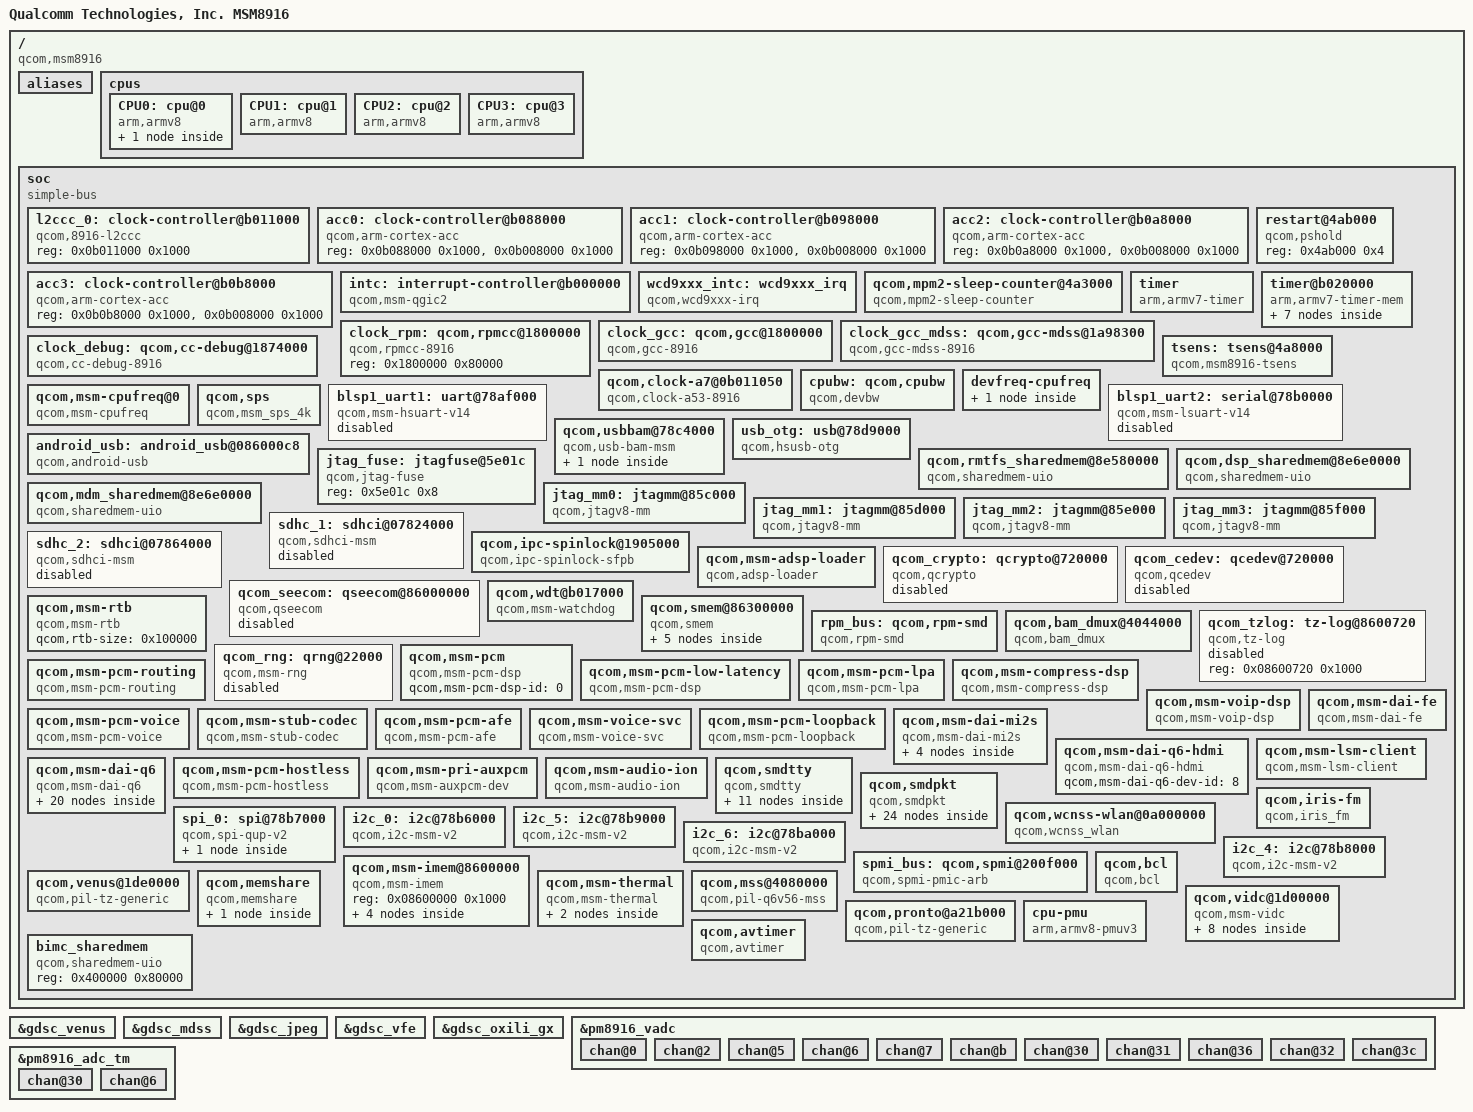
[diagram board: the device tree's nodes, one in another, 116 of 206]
/* Copyright (c) 2013-2014, The Linux Foundation. All rights reserved.
 *
 * This program is free software; you can redistribute it and/or modify
 * it under the terms of the GNU General Public License version 2 and
 * only version 2 as published by the Free Software Foundation.
 *
 * This program is distributed in the hope that it will be useful,
 * but WITHOUT ANY WARRANTY; without even the implied warranty of
 * MERCHANTABILITY or FITNESS FOR A PARTICULAR PURPOSE.  See the
 * GNU General Public License for more details.
 */

#include "skeleton64.dtsi"
#include <dt-bindings/clock/msm-clocks-8916.h>

/ {
	model = "Qualcomm Technologies, Inc. MSM8916";
	compatible = "qcom,msm8916";
	qcom,msm-id =	<206 0>,
			<248 0>,
			<249 0>,
			<250 0>;

	interrupt-parent = <&intc>;
	aliases {
		sdhc1 = &sdhc_1; /* SDC1 eMMC slot */
		sdhc2 = &sdhc_2; /* SDC2 SD card slot */

		/* smdtty devices */
		smd1 = &smdtty_apps_fm;
		smd2 = &smdtty_apps_riva_bt_acl;
		smd3 = &smdtty_apps_riva_bt_cmd;
		smd4 = &smdtty_mbalbridge;
		smd5 = &smdtty_apps_riva_ant_cmd;
		smd6 = &smdtty_apps_riva_ant_data;
		smd7 = &smdtty_data1;
		smd8 = &smdtty_data4;
		smd11 = &smdtty_data11;
		smd21 = &smdtty_data21;
		smd36 = &smdtty_loopback;

		spi0 = &spi_0; /* SPI0 controller device */
		i2c0 = &i2c_0; /* I2C0 controller device */
		i2c5 = &i2c_5; /* I2C5 controller device */
		i2c6 = &i2c_6; /* I2C6 NFC qup6 device */
		i2c4 = &i2c_4; /* I2C4 controller device */
	};

	cpus {
		#address-cells = <1>;
		#size-cells = <0>;

		CPU0: cpu@0 {
			device_type = "cpu";
			compatible = "arm,armv8";
			reg = <0x0>;
			enable-method = "qcom,arm-cortex-acc";
			qcom,acc = <&acc0>;
			next-level-cache = <&L2_0>;
			L2_0: l2-cache {
			      compatible = "arm,arch-cache";
			      cache-level = <2>;
			      power-domain = <&l2ccc_0>;
			};
		};

		CPU1: cpu@1 {
			device_type = "cpu";
			compatible = "arm,armv8";
			reg = <0x1>;
			enable-method = "qcom,arm-cortex-acc";
			qcom,acc = <&acc1>;
			next-level-cache = <&L2_0>;
		};

		CPU2: cpu@2 {
			device_type = "cpu";
			compatible = "arm,armv8";
			reg = <0x2>;
			enable-method = "qcom,arm-cortex-acc";
			qcom,acc = <&acc2>;
			next-level-cache = <&L2_0>;
		};

		CPU3: cpu@3 {
			device_type = "cpu";
			compatible = "arm,armv8";
			reg = <0x3>;
			enable-method = "qcom,arm-cortex-acc";
			qcom,acc = <&acc3>;
			next-level-cache = <&L2_0>;
		};
	};

	soc: soc { };
};

#include "msm8916-coresight.dtsi"
#include "msm8916-smp2p.dtsi"
#include "msm8916-pinctrl.dtsi"
#include "msm8916-camera.dtsi"
#include "msm8916-ipcrouter.dtsi"
#include "msm-gdsc-8916.dtsi"
#include "msm8916-iommu.dtsi"
#include "msm8916-gpu.dtsi"
#include "msm8916-mdss.dtsi"
#include "msm8916-mdss-pll.dtsi"
#include "msm8916-iommu-domains.dtsi"
#include "msm8916-bus.dtsi"
#include "msm8916-camera.dtsi"

&soc {
	#address-cells = <1>;
	#size-cells = <1>;
	ranges = <0 0 0 0xffffffff>;
	compatible = "simple-bus";

	l2ccc_0: clock-controller@b011000 {
		compatible = "qcom,8916-l2ccc";
		reg = <0x0b011000 0x1000>;
	};

	acc0:clock-controller@b088000 {
		compatible = "qcom,arm-cortex-acc";
		reg = <0x0b088000 0x1000>,
		      <0x0b008000 0x1000>;
	};

	acc1:clock-controller@b098000 {
		compatible = "qcom,arm-cortex-acc";
		reg = <0x0b098000 0x1000>,
		      <0x0b008000 0x1000>;
	};

	acc2:clock-controller@b0a8000 {
		compatible = "qcom,arm-cortex-acc";
		reg = <0x0b0a8000 0x1000>,
		      <0x0b008000 0x1000>;
	};

	acc3:clock-controller@b0b8000 {
		compatible = "qcom,arm-cortex-acc";
		reg = <0x0b0b8000 0x1000>,
		      <0x0b008000 0x1000>;
	};

	intc: interrupt-controller@b000000 {
		compatible = "qcom,msm-qgic2";
		interrupt-controller;
		#interrupt-cells = <3>;
		reg = <0x0b000000 0x1000>,
		<0x0b002000 0x1000>;
	};

	wcd9xxx_intc: wcd9xxx_irq {
		compatible = "qcom,wcd9xxx-irq";
		interrupt-controller;
		#interrupt-cells = <1>;
		interrupt-parent = <&intc>;
		interrupts = <0 68 0>;
		interrupt-names = "cdc-int";
	};

	restart@4ab000 {
		compatible = "qcom,pshold";
		reg = <0x4ab000 0x4>;
	};

	qcom,mpm2-sleep-counter@4a3000 {
		compatible = "qcom,mpm2-sleep-counter";
		reg = <0x4a3000 0x1000>;
		clock-frequency = <32768>;
	};

	timer {
		compatible = "arm,armv7-timer";
		interrupts = <1 2 0xf08>,
			     <1 3 0xf08>,
			     <1 4 0xf08>,
			     <1 1 0xf08>;
		clock-frequency = <19200000>;
	};

	timer@b020000 {
		#address-cells = <1>;
		#size-cells = <1>;
		ranges;
		compatible = "arm,armv7-timer-mem";
		reg = <0xb020000 0x1000>;
		clock-frequency = <19200000>;

		frame@b021000 {
			frame-number = <0>;
			interrupts = <0 8 0x4>,
				     <0 7 0x4>;
			reg = <0xb021000 0x1000>,
			      <0xb022000 0x1000>;
		};

		frame@b023000 {
			frame-number = <1>;
			interrupts = <0 9 0x4>;
			reg = <0xb023000 0x1000>;
			status = "disabled";
		};

		frame@b024000 {
			frame-number = <2>;
			interrupts = <0 10 0x4>;
			reg = <0xb024000 0x1000>;
			status = "disabled";
		};

		frame@b025000 {
			frame-number = <3>;
			interrupts = <0 11 0x4>;
			reg = <0xb025000 0x1000>;
			status = "disabled";
		};

		frame@b026000 {
			frame-number = <4>;
			interrupts = <0 12 0x4>;
			reg = <0xb026000 0x1000>;
			status = "disabled";
		};

		frame@b027000 {
			frame-number = <5>;
			interrupts = <0 13 0x4>;
			reg = <0xb027000 0x1000>;
			status = "disabled";
		};

		frame@b028000 {
			frame-number = <6>;
			interrupts = <0 14 0x4>;
			reg = <0xb028000 0x1000>;
			status = "disabled";
		};
	};

	clock_rpm: qcom,rpmcc@1800000 {
		compatible = "qcom,rpmcc-8916";
		reg = <0x1800000 0x80000>;
		reg-names = "cc_base";
		#clock-cells = <1>;

	};

	clock_gcc: qcom,gcc@1800000 {
		compatible = "qcom,gcc-8916";
		reg = <0x1800000 0x80000>,
		      <0xb016000 0x00040>;
		reg-names = "cc_base", "apcs_base";
		vdd_dig-supply = <&pm8916_s1_corner>;
		vdd_sr2_dig-supply = <&pm8916_s1_corner_ao>;
		vdd_sr2_pll-supply = <&pm8916_l7_ao>;
		clocks = <&clock_rpm clk_xo_clk_src>,
                         <&clock_rpm clk_xo_a_clk_src>;
		clock-names = "xo", "xo_a";
		#clock-cells = <1>;
	};

	clock_gcc_mdss: qcom,gcc-mdss@1a98300 {
		compatible = "qcom,gcc-mdss-8916";
		clocks = <&mdss_dsi0_pll clk_pixel_clk_src>,
			 <&mdss_dsi0_pll clk_byte_clk_src>;
		clock-names = "pixel_src", "byte_src";
		#clock-cells = <1>;
	};

	clock_debug: qcom,cc-debug@1874000 {
		compatible = "qcom,cc-debug-8916";
		reg = <0x1874000 0x4>,
		      <0xb01101c 0x8>;
		reg-names = "cc_base", "meas";
		clocks = <&clock_rpm clk_rpm_debug_mux>;
		clock-names = "rpm_debug_mux";
		#clock-cells = <1>;
	};

	tsens: tsens@4a8000 {
		compatible = "qcom,msm8916-tsens";
		reg = <0x4a8000 0x2000>,
		      <0x5c000  0x1000>;
		reg-names = "tsens_physical", "tsens_eeprom_physical";
		interrupts = <0 184 0>;
		qcom,sensors = <5>;
		qcom,slope = <3200 3200 3200 3200 3200>;
		qcom,sensor-id = <0 1 2 4 5>;
	};

	qcom,clock-a7@0b011050 {
		compatible = "qcom,clock-a53-8916";
		reg = <0x0b011050 0x8>;
		reg-names = "rcg-base";
		qcom,safe-freq = < 400000000 >;
		cpu-vdd-supply = <&apc_vreg_corner>;
		clocks = <&clock_gcc clk_gpll0_ao_clk_src>,
			 <&clock_gcc clk_a53sspll>;
		clock-names = "clk-4", "clk-5";
		qcom,speed0-bin-v0 =
			<          0 0>,
			<  200000000 1>,
			<  400000000 2>,
			<  533333000 3>,
			<  800000000 4>,
			<  998400000 5>,
			< 1094400000 6>,
			< 1190400000 7>;
	};

	cpubw: qcom,cpubw {
		compatible = "qcom,devbw";
		governor = "cpufreq";
		qcom,src-dst-ports = <1 512>;
		qcom,active-only;
		qcom,bw-tbl =
			/*  73 9.60 MHz */
			/* 381  50MHz */
			<  762 /* 100 MHz */>,
			< 1525 /* 200 MHz */>,
			< 3051 /* 400 MHz */>,
			< 4066 /* 533 MHz */>;
	};

	devfreq-cpufreq {
		cpubw-cpufreq {
			target-dev = <&cpubw>;
			cpu-to-dev-map =
				 <  400000  762>,
				 <  998400  1525>,
				 < 1094400  3051>,
				 < 1190400  4066>;
		};
	};

	qcom,msm-cpufreq@0 {
		reg = <0 4>;
		compatible = "qcom,msm-cpufreq";
		qcom,cpufreq-table =
			 <  200000 >,
			 <  400000 >,
			 <  533330 >,
			 <  800000 >,
			 <  998400 >,
			 < 1094400 >,
			 < 1190400 >;
	};

	qcom,sps {
		compatible = "qcom,msm_sps_4k";
		qcom,device-type = <3>;
		qcom,pipe-attr-ee;
	};

	blsp1_uart1: uart@78af000 {
		compatible = "qcom,msm-hsuart-v14";
		reg = <0x78af000 0x200>,
		      <0x7884000 0x23000>;
		reg-names = "core_mem", "bam_mem";
		interrupt-names = "core_irq", "bam_irq", "wakeup_irq";
		#address-cells = <0>;
		interrupt-parent = <&blsp1_uart1>;
		interrupts = <0 1 2>;
		#interrupt-cells = <1>;
		interrupt-map-mask = <0xffffffff>;
		interrupt-map = <0 &intc 0 107 0
				1 &intc 0 238 0
				2 &msm_gpio 1 0>;

		qcom,bam-tx-ep-pipe-index = <0>;
		qcom,bam-rx-ep-pipe-index = <1>;
		qcom,master-id = <86>;

		clocks = <&clock_gcc clk_gcc_blsp1_uart1_apps_clk>,
			 <&clock_gcc clk_gcc_blsp1_ahb_clk>;
		clock-names = "core_clk", "iface_clk";

		qcom,msm-bus,name = "blsp1_uart1";
		qcom,msm-bus,num-cases = <2>;
		qcom,msm-bus,num-paths = <1>;
		qcom,msm-bus,vectors-KBps =
				<86 512 0 0>,
				<86 512 500 800>;
		pinctrl-names = "sleep", "default";
		pinctrl-0 = <&hsuart_sleep>;
		pinctrl-1 = <&hsuart_active>;
		status = "disabled";
	};

	blsp1_uart2: serial@78b0000 {
		compatible = "qcom,msm-lsuart-v14";
		reg = <0x78b0000 0x200>;
		interrupts = <0 108 0>;
		status = "disabled";
		clocks = <&clock_gcc clk_gcc_blsp1_uart2_apps_clk>,
			 <&clock_gcc clk_gcc_blsp1_ahb_clk>;
		clock-names = "core_clk", "iface_clk";
	};

	qcom,usbbam@78c4000 {
		compatible = "qcom,usb-bam-msm";
		reg = <0x78c4000 0x15000>;
		reg-names = "hsusb";
		interrupts = <0 135 0>;
		interrupt-names = "hsusb";
		qcom,usb-bam-num-pipes = <2>;
		qcom,usb-bam-fifo-baseaddr = <0x08603800>;
		qcom,ignore-core-reset-ack;
		qcom,disable-clk-gating;

		qcom,pipe0 {
			label = "hsusb-qdss-in-0";
			qcom,usb-bam-mem-type = <3>;
			qcom,bam-type = <1>;
			qcom,dir = <1>;
			qcom,pipe-num = <0>;
			qcom,peer-bam = <1>;
			qcom,src-bam-physical-address = <0x884000>;
			qcom,src-bam-pipe-index = <0>;
			qcom,dst-bam-physical-address = <0x78c4000>;
			qcom,dst-bam-pipe-index = <0>;
			qcom,data-fifo-offset = <0x0>;
			qcom,data-fifo-size = <0x600>;
			qcom,descriptor-fifo-offset = <0x600>;
			qcom,descriptor-fifo-size = <0x200>;
			qcom,reset-bam-on-connect;
		};
	};

	usb_otg: usb@78d9000 {
		compatible = "qcom,hsusb-otg";

		reg = <0x78d9000 0x400>;
		interrupts = <0 134 0>,<0 140 0>;
		interrupt-names = "core_irq", "async_irq";

		hsusb_vdd_dig-supply = <&pm8916_s1_corner>;
		HSUSB_1p8-supply = <&pm8916_l7>;
		HSUSB_3p3-supply = <&pm8916_l13>;
		qcom,vdd-voltage-level = <1 5 7>;

		qcom,hsusb-otg-phy-init-seq =
			<0x44 0x80 0x6B 0x81 0x24 0x82 0x13 0x83 0xffffffff>;
		qcom,hsusb-otg-phy-type = <2>;
		qcom,hsusb-otg-mode = <1>;
		qcom,hsusb-otg-otg-control = <2>;
		qcom,dp-manual-pullup;

		qcom,msm-bus,name = "usb2";
		qcom,msm-bus,num-cases = <3>;
		qcom,msm-bus,num-paths = <1>;
		qcom,msm-bus,vectors-KBps =
				<87 512 0 0>,
				<87 512 60000 960000>,
				<87 512 6000  6000>;
		clocks = <&clock_gcc clk_gcc_usb_hs_ahb_clk>,
			 <&clock_gcc clk_gcc_usb_hs_system_clk>,
			 <&clock_gcc clk_gcc_usb2a_phy_sleep_clk>,
			 <&clock_rpm clk_xo_otg_clk>;
		clock-names = "iface_clk", "core_clk", "sleep_clk",
				"xo";
	};

	android_usb: android_usb@086000c8 {
		compatible = "qcom,android-usb";
		reg = <0x086000c8 0xc8>;
		qcom,pm-qos-latency = <2 1001 12701>;
		qcom,android-usb-uicc-nluns = /bits/ 8 <1>;
	};

	qcom,rmtfs_sharedmem@8e580000 {
		compatible = "qcom,sharedmem-uio";
		reg = <0x86700000 0xe0000>;
		reg-names = "rmtfs";
		qcom,client-id = <0x00000001>;
	};

	qcom,dsp_sharedmem@8e6e0000 {
		compatible = "qcom,sharedmem-uio";
		reg = <0x867e0000 0x20000>;
		reg-names = "rfsa_dsp";
		qcom,client-id = <0x011013ec>;
	};

	qcom,mdm_sharedmem@8e6e0000 {
		compatible = "qcom,sharedmem-uio";
		reg = <0x867e0000 0x20000>;
		reg-names = "rfsa_mdm";
		qcom,client-id = <0x011013ed>;
	};

	jtag_fuse: jtagfuse@5e01c {
		compatible = "qcom,jtag-fuse";
		reg = <0x5e01c 0x8>;
		reg-names = "fuse-base";
	};

	jtag_mm0: jtagmm@85c000 {
		compatible = "qcom,jtagv8-mm";
		reg = <0x85c000 0x1000>,
		      <0x850000 0x1000>;
		reg-names = "etm-base","debug-base";

		clocks = <&clock_rpm clk_qdss_clk>,
			 <&clock_rpm clk_qdss_a_clk>;
		clock-names = "core_clk", "core_a_clk";
	};

	jtag_mm1: jtagmm@85d000 {
		compatible = "qcom,jtagv8-mm";
		reg = <0x85d000 0x1000>,
		      <0x852000 0x1000>;
		reg-names = "etm-base","debug-base";

		clocks = <&clock_rpm clk_qdss_clk>,
			 <&clock_rpm clk_qdss_a_clk>;
		clock-names = "core_clk", "core_a_clk";
	};

	jtag_mm2: jtagmm@85e000 {
		compatible = "qcom,jtagv8-mm";
		reg = <0x85e000 0x1000>,
		      <0x854000 0x1000>;
		reg-names = "etm-base","debug-base";

		clocks = <&clock_rpm clk_qdss_clk>,
			 <&clock_rpm clk_qdss_a_clk>;
		clock-names = "core_clk", "core_a_clk";
	};

	jtag_mm3: jtagmm@85f000 {
		compatible = "qcom,jtagv8-mm";
		reg = <0x85f000 0x1000>,
		      <0x856000 0x1000>;
		reg-names = "etm-base","debug-base";

		clocks = <&clock_rpm clk_qdss_clk>,
			 <&clock_rpm clk_qdss_a_clk>;
		clock-names = "core_clk", "core_a_clk";
	};

	sdhc_1: sdhci@07824000 {
		compatible = "qcom,sdhci-msm";
		reg = <0x07824900 0x11c>, <0x07824000 0x800>;
		reg-names = "hc_mem", "core_mem";

		interrupts = <0 123 0>, <0 138 0>;
		interrupt-names = "hc_irq", "pwr_irq";

		qcom,bus-width = <8>;

		qcom,cpu-dma-latency-us = <701>;
		qcom,msm-bus,name = "sdhc1";
		qcom,msm-bus,num-cases = <8>;
		qcom,msm-bus,num-paths = <1>;
		qcom,msm-bus,vectors-KBps = <78 512 0 0>, /* No vote */
				<78 512 1600 3200>,    /* 400 KB/s*/
				<78 512 80000 160000>, /* 20 MB/s */
				<78 512 100000 200000>, /* 25 MB/s */
				<78 512 200000 400000>, /* 50 MB/s */
				<78 512 400000 800000>, /* 100 MB/s */
				<78 512 400000 800000>, /* 200 MB/s */
				<78 512 2048000 4096000>; /* Max. bandwidth */
		qcom,bus-bw-vectors-bps = <0 400000 20000000 25000000 50000000
						100000000 200000000 4294967295>;
		clocks = <&clock_gcc clk_gcc_sdcc1_ahb_clk>,
			 <&clock_gcc clk_gcc_sdcc1_apps_clk>;
		clock-names = "iface_clk", "core_clk";

		qcom,clk-rates = <400000 25000000 50000000 100000000 177770000>;
		qcom,bus-speed-mode = "HS200_1p8v", "DDR_1p8v";

		status = "disabled";
	};

	sdhc_2: sdhci@07864000 {
		compatible = "qcom,sdhci-msm";
		reg = <0x07864900 0x11c>, <0x07864000 0x800>;
		reg-names = "hc_mem", "core_mem";

		interrupts = <0 125 0>, <0 221 0>;
		interrupt-names = "hc_irq", "pwr_irq";

		qcom,bus-width = <4>;

		qcom,cpu-dma-latency-us = <701>;
		qcom,msm-bus,name = "sdhc2";
		qcom,msm-bus,num-cases = <8>;
		qcom,msm-bus,num-paths = <1>;
		qcom,msm-bus,vectors-KBps = <81 512 0 0>, /* No vote */
				<81 512 1600 3200>,    /* 400 KB/s*/
				<81 512 80000 160000>, /* 20 MB/s */
				<81 512 100000 200000>, /* 25 MB/s */
				<81 512 200000 400000>, /* 50 MB/s */
				<81 512 400000 800000>, /* 100 MB/s */
				<81 512 400000 800000>, /* 200 MB/s */
				<81 512 2048000 4096000>; /* Max. bandwidth */
		qcom,bus-bw-vectors-bps = <0 400000 20000000 25000000 50000000
						100000000 200000000 4294967295>;
		clocks = <&clock_gcc clk_gcc_sdcc2_ahb_clk>,
			 <&clock_gcc clk_gcc_sdcc2_apps_clk>;
		clock-names = "iface_clk", "core_clk";

		qcom,clk-rates = <400000 25000000 50000000 100000000 200000000>;

		status = "disabled";
	};

	qcom,ipc-spinlock@1905000 {
		compatible = "qcom,ipc-spinlock-sfpb";
		reg = <0x1905000 0x8000>;
		qcom,num-locks = <8>;
	};

	qcom,msm-adsp-loader {
		compatible = "qcom,adsp-loader";
		qcom,adsp-state = <0>;
		qcom,proc-img-to-load = "modem";
	};

	qcom_crypto: qcrypto@720000 {
		compatible = "qcom,qcrypto";
		reg = <0x720000 0x20000>,
		      <0x704000 0x20000>;
		reg-names = "crypto-base","crypto-bam-base";
		interrupts = <0 207 0>;
		qcom,bam-pipe-pair = <2>;
		qcom,ce-hw-instance = <0>;
		qcom,ce-device = <0>;
		qcom,msm-bus,name = "qcrypto-noc";
		qcom,msm-bus,num-cases = <2>;
		qcom,msm-bus,num-paths = <1>;
		qcom,msm-bus,vectors-KBps =
				<55 512 0 0>,
				<55 512 3936000 393600>;
		clocks = <&clock_gcc clk_crypto_clk_src>,
			 <&clock_gcc clk_gcc_crypto_clk>,
			 <&clock_gcc clk_gcc_crypto_ahb_clk>,
			 <&clock_gcc clk_gcc_crypto_axi_clk>;
		clock-names = "core_clk_src", "core_clk",
				"iface_clk", "bus_clk";
		qcom,use-sw-aes-cbc-ecb-ctr-algo;
		qcom,use-sw-aes-xts-algo;
		qcom,use-sw-ahash-algo;
		status = "disabled";
	};

	qcom_cedev: qcedev@720000 {
		compatible = "qcom,qcedev";
		reg = <0x720000 0x20000>,
		      <0x704000 0x20000>;
		reg-names = "crypto-base","crypto-bam-base";
		interrupts = <0 207 0>;
		qcom,bam-pipe-pair = <1>;
		qcom,ce-hw-instance = <0>;
		qcom,ce-device = <0>;
		qcom,ce-hw-shared;
		qcom,msm-bus,name = "qcedev-noc";
		qcom,msm-bus,num-cases = <2>;
		qcom,msm-bus,num-paths = <1>;
		qcom,msm-bus,vectors-KBps =
				<55 512 0 0>,
				<55 512 3936000 393600>;
		clocks = <&clock_gcc clk_crypto_clk_src>,
			 <&clock_gcc clk_gcc_crypto_clk>,
			 <&clock_gcc clk_gcc_crypto_ahb_clk>,
			 <&clock_gcc clk_gcc_crypto_axi_clk>;
		clock-names = "core_clk_src", "core_clk",
				"iface_clk", "bus_clk";
		status = "disabled";
	};

	qcom_seecom: qseecom@86000000 {
		compatible = "qcom,qseecom";
		reg = <0x86000000 0x300000>;
		reg-names = "secapp-region";
		qcom,disk-encrypt-pipe-pair = <2>;
		qcom,hlos-ce-hw-instance = <0>;
		qcom,qsee-ce-hw-instance = <0>;
		qcom,msm-bus,name = "qseecom-noc";
		qcom,msm-bus,num-cases = <4>;
		qcom,msm-bus,num-paths = <1>;
		qcom,support-bus-scaling;
		qcom,msm-bus,vectors-KBps =
				<55 512 0 0>,
				<55 512 0 0>,
				<55 512 120000 1200000>,
				<55 512 393600 3936000>;
		clocks = <&clock_gcc clk_crypto_clk_src>,
			 <&clock_gcc clk_gcc_crypto_clk>,
			 <&clock_gcc clk_gcc_crypto_ahb_clk>,
			 <&clock_gcc clk_gcc_crypto_axi_clk>;
		clock-names = "core_clk_src", "core_clk",
				"iface_clk", "bus_clk";
		status = "disabled";
	};

	qcom,wdt@b017000 {
		compatible = "qcom,msm-watchdog";
		reg = <0xb017000 0x1000>;
		reg-names = "wdt-base";
		interrupts = <0 3 0>, <0 4 0>;
		qcom,bark-time = <11000>;
		qcom,pet-time = <10000>;
		qcom,ipi-ping;
	};

	qcom,msm-rtb {
		compatible = "qcom,msm-rtb";
		qcom,rtb-size = <0x100000>;
	};

	qcom,smem@86300000 {
		compatible = "qcom,smem";
		reg = <0x86300000 0x100000>,
			<0x0b011008 0x4>,
			<0x60000 0x8000>,
			<0x193D000 0x8>;
		reg-names = "smem", "irq-reg-base", "aux-mem1", "smem_targ_info_reg";
		qcom,mpu-enabled;

		qcom,smd-modem {
			compatible = "qcom,smd";
			qcom,smd-edge = <0>;
			qcom,smd-irq-offset = <0x0>;
			qcom,smd-irq-bitmask = <0x1000>;
			interrupts = <0 25 1>;
			label = "modem";
		};

		qcom,smsm-modem {
			compatible = "qcom,smsm";
			qcom,smsm-edge = <0>;
			qcom,smsm-irq-offset = <0x0>;
			qcom,smsm-irq-bitmask = <0x2000>;
			interrupts = <0 26 1>;
		};

		qcom,smd-wcnss {
			compatible = "qcom,smd";
			qcom,smd-edge = <6>;
			qcom,smd-irq-offset = <0x0>;
			qcom,smd-irq-bitmask = <0x20000>;
			interrupts = <0 142 1>;
			label = "wcnss";
		};

		qcom,smsm-wcnss {
			compatible = "qcom,smsm";
			qcom,smsm-edge = <6>;
			qcom,smsm-irq-offset = <0x0>;
			qcom,smsm-irq-bitmask = <0x80000>;
			interrupts = <0 144 1>;
		};

		qcom,smd-rpm {
			compatible = "qcom,smd";
			qcom,smd-edge = <15>;
			qcom,smd-irq-offset = <0x0>;
			qcom,smd-irq-bitmask = <0x1>;
			interrupts = <0 168 1>;
			label = "rpm";
			qcom,irq-no-suspend;
			qcom,not-loadable;
		};
	};

        rpm_bus: qcom,rpm-smd {
                compatible = "qcom,rpm-smd";
                rpm-channel-name = "rpm_requests";
                rpm-channel-type = <15>; /* SMD_APPS_RPM */
        };

	qcom,bam_dmux@4044000 {
		compatible = "qcom,bam_dmux";
		reg = <0x4044000 0x19000>;
		interrupts = <0 29 1>;
		qcom,rx-ring-size = <32>;
		qcom,max-rx-mtu = <4096>;
	};

	qcom_tzlog: tz-log@8600720 {
		compatible = "qcom,tz-log";
		reg = <0x08600720 0x1000>;
		status = "disabled";
	};

	qcom_rng: qrng@22000 {
		compatible = "qcom,msm-rng";
		reg = <0x22000 0x200>;
		qcom,msm-rng-iface-clk;
		qcom,msm-bus,name = "msm-rng-noc";
		qcom,msm-bus,num-cases = <2>;
		qcom,msm-bus,num-paths = <1>;
		qcom,msm-bus,vectors-KBps =
				<1 618 0 0>,		/* No vote */
				<1 618 0 800>;		/* 100 MB/s */
		clocks = <&clock_gcc clk_gcc_prng_ahb_clk>;
		clock-names = "iface_clk";
		status = "disabled";
	};

	qcom,msm-pcm {
		compatible = "qcom,msm-pcm-dsp";
		qcom,msm-pcm-dsp-id = <0>;
	};

	qcom,msm-pcm-routing {
		compatible = "qcom,msm-pcm-routing";
	};

	qcom,msm-pcm-low-latency {
		compatible = "qcom,msm-pcm-dsp";
		qcom,msm-pcm-dsp-id = <1>;
		qcom,msm-pcm-low-latency;
		qcom,latency-level = "ultra";
	};

	qcom,msm-pcm-lpa {
		compatible = "qcom,msm-pcm-lpa";
	};

	qcom,msm-compress-dsp {
		compatible = "qcom,msm-compress-dsp";
	};

	qcom,msm-voip-dsp {
		compatible = "qcom,msm-voip-dsp";
	};

	qcom,msm-pcm-voice {
		compatible = "qcom,msm-pcm-voice";
		qcom,destroy-cvd;
		qcom,vote-bms;
	};

	qcom,msm-stub-codec {
		compatible = "qcom,msm-stub-codec";
	};

	qcom,msm-dai-fe {
		compatible = "qcom,msm-dai-fe";
	};

	qcom,msm-pcm-afe {
		compatible = "qcom,msm-pcm-afe";
	};

	qcom,msm-voice-svc {
		compatible = "qcom,msm-voice-svc";
	};

	qcom,msm-pcm-loopback {
		compatible = "qcom,msm-pcm-loopback";
	};

	qcom,msm-dai-mi2s {
		compatible = "qcom,msm-dai-mi2s";
		qcom,msm-dai-q6-mi2s-prim {
			compatible = "qcom,msm-dai-q6-mi2s";
			qcom,msm-dai-q6-mi2s-dev-id = <0>;
			qcom,msm-mi2s-rx-lines = <3>;
			qcom,msm-mi2s-tx-lines = <0>;
		};

		qcom,msm-dai-q6-mi2s-sec {
			compatible = "qcom,msm-dai-q6-mi2s";
			qcom,msm-dai-q6-mi2s-dev-id = <1>;
			qcom,msm-mi2s-rx-lines = <1>;
			qcom,msm-mi2s-tx-lines = <0>;
		};

		qcom,msm-dai-q6-mi2s-quat {
			compatible = "qcom,msm-dai-q6-mi2s";
			qcom,msm-dai-q6-mi2s-dev-id = <3>;
			qcom,msm-mi2s-rx-lines = <1>;
			qcom,msm-mi2s-tx-lines = <2>;
		};

		qcom,msm-dai-q6-mi2s-tert {
			compatible = "qcom,msm-dai-q6-mi2s";
			qcom,msm-dai-q6-mi2s-dev-id = <2>;
			qcom,msm-mi2s-rx-lines = <0>;
			qcom,msm-mi2s-tx-lines = <3>;
		};
	};

	qcom,msm-dai-q6-hdmi {
		compatible = "qcom,msm-dai-q6-hdmi";
		qcom,msm-dai-q6-dev-id = <8>;
	};

	qcom,msm-lsm-client {
		compatible = "qcom,msm-lsm-client";
	};

	qcom,msm-dai-q6 {
		compatible = "qcom,msm-dai-q6";
		qcom,msm-dai-q6-sb-0-rx {
			compatible = "qcom,msm-dai-q6-dev";
			qcom,msm-dai-q6-dev-id = <16384>;
		};

		qcom,msm-dai-q6-sb-0-tx {
			compatible = "qcom,msm-dai-q6-dev";
			qcom,msm-dai-q6-dev-id = <16385>;
		};

		qcom,msm-dai-q6-sb-1-rx {
			compatible = "qcom,msm-dai-q6-dev";
			qcom,msm-dai-q6-dev-id = <16386>;
		};

		qcom,msm-dai-q6-sb-1-tx {
			compatible = "qcom,msm-dai-q6-dev";
			qcom,msm-dai-q6-dev-id = <16387>;
		};

		qcom,msm-dai-q6-sb-3-rx {
			compatible = "qcom,msm-dai-q6-dev";
			qcom,msm-dai-q6-dev-id = <16390>;
		};

		qcom,msm-dai-q6-sb-3-tx {
			compatible = "qcom,msm-dai-q6-dev";
			qcom,msm-dai-q6-dev-id = <16391>;
		};

		qcom,msm-dai-q6-sb-4-rx {
			compatible = "qcom,msm-dai-q6-dev";
			qcom,msm-dai-q6-dev-id = <16392>;
		};

		qcom,msm-dai-q6-sb-4-tx {
			compatible = "qcom,msm-dai-q6-dev";
			qcom,msm-dai-q6-dev-id = <16393>;
		};

		qcom,msm-dai-q6-bt-sco-rx {
			compatible = "qcom,msm-dai-q6-dev";
			qcom,msm-dai-q6-dev-id = <12288>;
		};

		qcom,msm-dai-q6-bt-sco-tx {
			compatible = "qcom,msm-dai-q6-dev";
			qcom,msm-dai-q6-dev-id = <12289>;
		};

		qcom,msm-dai-q6-int-fm-rx {
			compatible = "qcom,msm-dai-q6-dev";
			qcom,msm-dai-q6-dev-id = <12292>;
		};

		qcom,msm-dai-q6-int-fm-tx {
			compatible = "qcom,msm-dai-q6-dev";
			qcom,msm-dai-q6-dev-id = <12293>;
		};

		qcom,msm-dai-q6-be-afe-pcm-rx {
			compatible = "qcom,msm-dai-q6-dev";
			qcom,msm-dai-q6-dev-id = <224>;
		};

		qcom,msm-dai-q6-be-afe-pcm-tx {
			compatible = "qcom,msm-dai-q6-dev";
			qcom,msm-dai-q6-dev-id = <225>;
		};

		qcom,msm-dai-q6-afe-proxy-rx {
			compatible = "qcom,msm-dai-q6-dev";
			qcom,msm-dai-q6-dev-id = <241>;
		};

		qcom,msm-dai-q6-afe-proxy-tx {
			compatible = "qcom,msm-dai-q6-dev";
			qcom,msm-dai-q6-dev-id = <240>;
		};

		qcom,msm-dai-q6-incall-record-rx {
			compatible = "qcom,msm-dai-q6-dev";
			qcom,msm-dai-q6-dev-id = <32771>;
		};

		qcom,msm-dai-q6-incall-record-tx {
			compatible = "qcom,msm-dai-q6-dev";
			qcom,msm-dai-q6-dev-id = <32772>;
		};

		qcom,msm-dai-q6-incall-music-rx {
			compatible = "qcom,msm-dai-q6-dev";
			qcom,msm-dai-q6-dev-id = <32773>;
		};

		qcom,msm-dai-q6-incall-music-2-rx {
			compatible = "qcom,msm-dai-q6-dev";
			qcom,msm-dai-q6-dev-id = <32770>;
		};
	};

	qcom,msm-pcm-hostless {
		compatible = "qcom,msm-pcm-hostless";
	};

	qcom,msm-pri-auxpcm {
		compatible = "qcom,msm-auxpcm-dev";
		qcom,msm-cpudai-auxpcm-mode = <0>, <0>;
		qcom,msm-cpudai-auxpcm-sync = <1>, <1>;
		qcom,msm-cpudai-auxpcm-frame = <5>, <4>;
		qcom,msm-cpudai-auxpcm-quant = <2>, <2>;
		qcom,msm-cpudai-auxpcm-num-slots = <1>, <1>;
		qcom,msm-cpudai-auxpcm-slot-mapping = <1>, <1>;
		qcom,msm-cpudai-auxpcm-data = <0>, <0>;
		qcom,msm-cpudai-auxpcm-pcm-clk-rate = <2048000>, <2048000>;
		qcom,msm-auxpcm-interface = "primary";
	};

	qcom,msm-audio-ion {
		compatible = "qcom,msm-audio-ion";
	};

	qcom,smdtty {
		compatible = "qcom,smdtty";

		smdtty_apps_fm: qcom,smdtty-apps-fm {
			qcom,smdtty-remote = "wcnss";
			qcom,smdtty-port-name = "APPS_FM";
		};

		smdtty_apps_riva_bt_acl: smdtty-apps-riva-bt-acl {
			qcom,smdtty-remote = "wcnss";
			qcom,smdtty-port-name = "APPS_RIVA_BT_ACL";
		};

		smdtty_apps_riva_bt_cmd: qcom,smdtty-apps-riva-bt-cmd {
			qcom,smdtty-remote = "wcnss";
			qcom,smdtty-port-name = "APPS_RIVA_BT_CMD";
		};

		smdtty_mbalbridge: qcom,smdtty-mbalbridge {
			qcom,smdtty-remote = "modem";
			qcom,smdtty-port-name = "MBALBRIDGE";
		};

		smdtty_apps_riva_ant_cmd: smdtty-apps-riva-ant-cmd {
			qcom,smdtty-remote = "wcnss";
			qcom,smdtty-port-name = "APPS_RIVA_ANT_CMD";
		};

		smdtty_apps_riva_ant_data: smdtty-apps-riva-ant-data {
			qcom,smdtty-remote = "wcnss";
			qcom,smdtty-port-name = "APPS_RIVA_ANT_DATA";
		};

		smdtty_data1: qcom,smdtty-data1 {
			qcom,smdtty-remote = "modem";
			qcom,smdtty-port-name = "DATA1";
		};

		smdtty_data4: qcom,smdtty-data4 {
			qcom,smdtty-remote = "modem";
			qcom,smdtty-port-name = "DATA4";
		};

		smdtty_data11: qcom,smdtty-data11 {
			qcom,smdtty-remote = "modem";
			qcom,smdtty-port-name = "DATA11";
		};

		smdtty_data21: qcom,smdtty-data21 {
			qcom,smdtty-remote = "modem";
			qcom,smdtty-port-name = "DATA21";
		};

		smdtty_loopback: smdtty-loopback {
			qcom,smdtty-remote = "modem";
			qcom,smdtty-port-name = "LOOPBACK";
			qcom,smdtty-dev-name = "LOOPBACK_TTY";
		};
	};

	qcom,smdpkt {
		compatible = "qcom,smdpkt";

		qcom,smdpkt-data5-cntl {
			qcom,smdpkt-remote = "modem";
			qcom,smdpkt-port-name = "DATA5_CNTL";
			qcom,smdpkt-dev-name = "smdcntl0";
		};

		qcom,smdpkt-data6-cntl {
			qcom,smdpkt-remote = "modem";
			qcom,smdpkt-port-name = "DATA6_CNTL";
			qcom,smdpkt-dev-name = "smdcntl1";
		};

		qcom,smdpkt-data7-cntl {
			qcom,smdpkt-remote = "modem";
			qcom,smdpkt-port-name = "DATA7_CNTL";
			qcom,smdpkt-dev-name = "smdcntl2";
		};

		qcom,smdpkt-data8-cntl {
			qcom,smdpkt-remote = "modem";
			qcom,smdpkt-port-name = "DATA8_CNTL";
			qcom,smdpkt-dev-name = "smdcntl3";
		};

		qcom,smdpkt-data9-cntl {
			qcom,smdpkt-remote = "modem";
			qcom,smdpkt-port-name = "DATA9_CNTL";
			qcom,smdpkt-dev-name = "smdcntl4";
		};

		qcom,smdpkt-data12-cntl {
			qcom,smdpkt-remote = "modem";
			qcom,smdpkt-port-name = "DATA12_CNTL";
			qcom,smdpkt-dev-name = "smdcntl5";
		};

		qcom,smdpkt-data13-cntl {
			qcom,smdpkt-remote = "modem";
			qcom,smdpkt-port-name = "DATA13_CNTL";
			qcom,smdpkt-dev-name = "smdcntl6";
		};

		qcom,smdpkt-data14-cntl {
			qcom,smdpkt-remote = "modem";
			qcom,smdpkt-port-name = "DATA14_CNTL";
			qcom,smdpkt-dev-name = "smdcntl7";
		};

		qcom,smdpkt-data15-cntl {
			qcom,smdpkt-remote = "modem";
			qcom,smdpkt-port-name = "DATA15_CNTL";
			qcom,smdpkt-dev-name = "smdcntl9";
		};

		qcom,smdpkt-data16-cntl {
			qcom,smdpkt-remote = "modem";
			qcom,smdpkt-port-name = "DATA16_CNTL";
			qcom,smdpkt-dev-name = "smdcntl10";
		};

		qcom,smdpkt-data17-cntl {
			qcom,smdpkt-remote = "modem";
			qcom,smdpkt-port-name = "DATA17_CNTL";
			qcom,smdpkt-dev-name = "smdcntl11";
		};

		qcom,smdpkt-data22 {
			qcom,smdpkt-remote = "modem";
			qcom,smdpkt-port-name = "DATA22";
			qcom,smdpkt-dev-name = "smd22";
		};

		qcom,smdpkt-data23-cntl {
			qcom,smdpkt-remote = "modem";
			qcom,smdpkt-port-name = "DATA23_CNTL";
			qcom,smdpkt-dev-name = "smdcnt_rev0";
		};

		qcom,smdpkt-data24-cntl {
			qcom,smdpkt-remote = "modem";
			qcom,smdpkt-port-name = "DATA24_CNTL";
			qcom,smdpkt-dev-name = "smdcnt_rev1";
		};

		qcom,smdpkt-data25-cntl {
			qcom,smdpkt-remote = "modem";
			qcom,smdpkt-port-name = "DATA25_CNTL";
			qcom,smdpkt-dev-name = "smdcnt_rev2";
		};

		qcom,smdpkt-data26-cntl {
			qcom,smdpkt-remote = "modem";
			qcom,smdpkt-port-name = "DATA26_CNTL";
			qcom,smdpkt-dev-name = "smdcnt_rev3";
		};

		qcom,smdpkt-data27-cntl {
			qcom,smdpkt-remote = "modem";
			qcom,smdpkt-port-name = "DATA27_CNTL";
			qcom,smdpkt-dev-name = "smdcnt_rev4";
		};

		qcom,smdpkt-data28-cntl {
			qcom,smdpkt-remote = "modem";
			qcom,smdpkt-port-name = "DATA28_CNTL";
			qcom,smdpkt-dev-name = "smdcnt_rev5";
		};

		qcom,smdpkt-data29-cntl {
			qcom,smdpkt-remote = "modem";
			qcom,smdpkt-port-name = "DATA29_CNTL";
			qcom,smdpkt-dev-name = "smdcnt_rev6";
		};

		qcom,smdpkt-data30-cntl {
			qcom,smdpkt-remote = "modem";
			qcom,smdpkt-port-name = "DATA30_CNTL";
			qcom,smdpkt-dev-name = "smdcnt_rev7";
		};

		qcom,smdpkt-data31-cntl {
			qcom,smdpkt-remote = "modem";
			qcom,smdpkt-port-name = "DATA31_CNTL";
			qcom,smdpkt-dev-name = "smdcnt_rev8";
		};

		qcom,smdpkt-data40-cntl {
			qcom,smdpkt-remote = "modem";
			qcom,smdpkt-port-name = "DATA40_CNTL";
			qcom,smdpkt-dev-name = "smdcntl8";
		};

		qcom,smdpkt-apr-apps2 {
			qcom,smdpkt-remote = "modem";
			qcom,smdpkt-port-name = "apr_apps2";
			qcom,smdpkt-dev-name = "apr_apps2";
		};

		qcom,smdpkt-loopback {
			qcom,smdpkt-remote = "modem";
			qcom,smdpkt-port-name = "LOOPBACK";
			qcom,smdpkt-dev-name = "smd_pkt_loopback";
		};
	};

	qcom,iris-fm {
		compatible = "qcom,iris_fm";
	};

	qcom,wcnss-wlan@0a000000 {
		compatible = "qcom,wcnss_wlan";
		reg = <0x0a000000 0x280000>,
			<0xb011008 0x04>,
			<0x0a21b000 0x3000>,
			<0x03204000 0x00000100>,
			<0x03200800 0x00000200>,
			<0x0A100400 0x00000200>,
			<0x0A205050 0x00000200>,
			<0x0A219000 0x00000020>,
			<0x0A080488 0x00000008>,
			<0x0A080fb0 0x00000008>,
			<0x0A08040c 0x00000008>,
			<0x0A0120a8 0x00000008>,
			<0x0A012448 0x00000008>,
			<0x0A080c00 0x00000001>;

		reg-names = "wcnss_mmio", "wcnss_fiq",
			    "pronto_phy_base", "riva_phy_base",
			    "riva_ccu_base", "pronto_a2xb_base",
			    "pronto_ccpu_base", "pronto_saw2_base",
			    "wlan_tx_phy_aborts","wlan_brdg_err_source",
			    "wlan_tx_status", "alarms_txctl",
			    "alarms_tactl", "pronto_mcu_base";

		interrupts = <0 145 0 0 146 0>;
		interrupt-names = "wcnss_wlantx_irq", "wcnss_wlanrx_irq";

		qcom,pronto-vddmx-supply = <&pm8916_l3>;
		qcom,pronto-vddcx-supply = <&pm8916_s1_corner>;
		qcom,pronto-vddpx-supply = <&pm8916_l7>;
		qcom,iris-vddxo-supply   = <&pm8916_l7>;
		qcom,iris-vddrfa-supply  = <&pm8916_s3>;
		qcom,iris-vddpa-supply   = <&pm8916_l9>;
		qcom,iris-vdddig-supply  = <&pm8916_l5>;

		pinctrl-names = "wcnss_default", "wcnss_sleep",
						"wcnss_gpio_default";
		pinctrl-0 = <&wcnss_default>;
		pinctrl-1 = <&wcnss_sleep>;
		pinctrl-2 = <&wcnss_gpio_default>;

		gpios = <&msm_gpio 40 0>, <&msm_gpio 41 0>, <&msm_gpio 42 0>,
					<&msm_gpio 43 0>, <&msm_gpio 44 0>;

		clocks = <&clock_rpm clk_xo_wlan_clk>,
			 <&clock_rpm clk_rf_clk2>,
			 <&clock_debug clk_gcc_debug_mux>,
			 <&clock_gcc clk_wcnss_m_clk>;
		clock-names = "xo", "rf_clk", "measure", "wcnss_debug";

		qcom,has-autodetect-xo;
		qcom,wlan-rx-buff-count = <512>;
		qcom,is-pronto-vt;
		qcom,has-pronto-hw;
		qcom,wcnss-adc_tm = <&pm8916_adc_tm>;
	};

	spi_0: spi@78b7000 { /* BLSP1 QUP3 */
		compatible = "qcom,spi-qup-v2";
                #address-cells = <1>;
                #size-cells = <0>;
                reg-names = "spi_physical", "spi_bam_physical";
                reg = <0x78b7000 0x600>,
                      <0x7884000 0x23000>;
                interrupt-names = "spi_irq", "spi_bam_irq";
                interrupts = <0 97 0>, <0 238 0>;
                spi-max-frequency = <50000000>;
                pinctrl-names = "default", "sleep";
                pinctrl-0 = <&spi0_default &spi0_cs0_active>;
		pinctrl-1 = <&spi0_sleep &spi0_cs0_sleep>;
		clocks = <&clock_gcc clk_gcc_blsp1_ahb_clk>,
			 <&clock_gcc clk_gcc_blsp1_qup3_spi_apps_clk>;
		clock-names = "iface_clk", "core_clk";
                qcom,infinite-mode = <0>;
		qcom,use-bam;
		qcom,use-pinctrl;
                qcom,ver-reg-exists;
                qcom,bam-consumer-pipe-index = <8>;
                qcom,bam-producer-pipe-index = <9>;
                qcom,master-id = <86>;

		lattice,spi-usb@0 {
			compatible = "lattice,ice40-spi-usb";
			reg = <0>;
			spi-max-frequency = <50000000>;
			spi-cpol = <1>;
			spi-cpha = <1>;
			core-vcc-supply = <&pm8916_l2>;
			spi-vcc-supply = <&pm8916_l5>;
			lattice,reset-gpio = <&msm_gpio 3 0>;
			lattice,config-done-gpio = <&msm_gpio 1 0>;
			lattice,vcc-en-gpio = <&msm_gpio 114 0>;
			lattice,clk-en-gpio = <&msm_gpio 0 0>;

			clocks = <&clock_rpm clk_bb_clk2_pin>;
			clock-names = "xo";
			pinctrl-names = "default", "sleep";
			pinctrl-0 = <&ice40_default>;
			pinctrl-1 = <&ice40_sleep>;
		};
        };

	i2c_0: i2c@78b6000 { /* BLSP1 QUP2 */
		compatible = "qcom,i2c-msm-v2";
		#address-cells = <1>;
		#size-cells = <0>;
		reg-names = "qup_phys_addr", "bam_phys_addr";
		reg = <0x78b6000 0x600>,
		      <0x7884000 0x23000>;
		interrupt-names = "qup_irq", "bam_irq";
		interrupts = <0 96 0>, <0 238 0>;
		clocks = <&clock_gcc clk_gcc_blsp1_ahb_clk>,
			 <&clock_gcc clk_gcc_blsp1_qup2_i2c_apps_clk>;
		clock-names = "iface_clk", "core_clk";
		qcom,clk-freq-out = <100000>;
		qcom,clk-freq-in  = <19200000>;
		pinctrl-names = "i2c_active", "i2c_sleep";
		pinctrl-0 = <&i2c_0_active>;
		pinctrl-1 = <&i2c_0_sleep>;
		qcom,noise-rjct-scl = <0>;
		qcom,noise-rjct-sda = <0>;
		qcom,bam-pipe-idx-cons = <6>;
		qcom,bam-pipe-idx-prod = <7>;
		qcom,master-id = <86>;
	};

	i2c_5: i2c@78b9000 { /* BLSP1 QUP5 */
		compatible = "qcom,i2c-msm-v2";
		#address-cells = <1>;
		#size-cells = <0>;
		reg-names = "qup_phys_addr", "bam_phys_addr";
		reg = <0x78b9000 0x600>,
		      <0x7884000 0x23000>;
		interrupt-names = "qup_irq", "bam_irq";
		interrupts = <0 99 0>, <0 238 0>;
		clocks = <&clock_gcc clk_gcc_blsp1_ahb_clk>,
			 <&clock_gcc clk_gcc_blsp1_qup5_i2c_apps_clk>;
		clock-names = "iface_clk", "core_clk";
		qcom,clk-freq-out = <100000>;
		qcom,clk-freq-in  = <19200000>;
		pinctrl-names = "i2c_active", "i2c_sleep";
		pinctrl-0 = <&i2c_5_active>;
		pinctrl-1 = <&i2c_5_sleep>;
		qcom,noise-rjct-scl = <0>;
		qcom,noise-rjct-sda = <0>;
		qcom,bam-pipe-idx-cons = <12>;
		qcom,bam-pipe-idx-prod = <13>;
		qcom,master-id = <86>;
	};

	i2c_6: i2c@78ba000 { /* BLSP1 QUP6 */
		compatible = "qcom,i2c-msm-v2";
		#address-cells=<1>;
		#size-cells=<0>;
		cell-index = <6>;
		reg-names = "qup_phys_addr", "bam_phys_addr";
		reg = <0x78ba000 0x1000>,
		      <0x7884000 0x23000>;
		interrupt-names = "qup_irq", "bam_irq";
		interrupts = <0 100 0>, <0 238 0>;
		clocks = <&clock_gcc clk_gcc_blsp1_ahb_clk>,
			 <&clock_gcc clk_gcc_blsp1_qup6_i2c_apps_clk>;
		clock-names = "iface_clk", "core_clk";
		qcom,clk-freq-out = <400000>;
		qcom,clk-freq-in  = <19200000>;
		pinctrl-names = "i2c_active", "i2c_sleep";
		pinctrl-0 = <&i2c_6_active>;
		pinctrl-1 = <&i2c_6_sleep>;
		qcom,noise-rjct-scl = <0>;
		qcom,noise-rjct-sda = <0>;
		qcom,bam-pipe-idx-cons = <14>;
		qcom,bam-pipe-idx-prod = <15>;
		qcom,master-id = <86>;
	};

	i2c_4: i2c@78b8000 { /* BLSP1 QUP4 */
		compatible = "qcom,i2c-msm-v2";
		#address-cells = <1>;
		#size-cells = <0>;
		reg-names = "qup_phys_addr", "bam_phys_addr";
		reg = <0x78b8000 0x1000>,
			<0x7884000 0x23f00>;
		interrupt-names = "qup_irq", "bam_irq";
		interrupts = <0 98 0>, <0 238 0>;
		qcom,clk-freq-out = <400000>;
		qcom,clk-freq-in  = <19200000>;
		clock-names = "iface_clk", "core_clk";
		clocks = <&clock_gcc clk_gcc_blsp1_ahb_clk>,
			<&clock_gcc clk_gcc_blsp1_qup4_i2c_apps_clk>;
		qcom,use-pinctrl;
		pinctrl-names = "i2c_active", "i2c_sleep";
		pinctrl-0 = <&i2c_4_active>;
		pinctrl-1 = <&i2c_4_sleep>;
		qcom,noise-rjct-scl = <0>;
		qcom,noise-rjct-sda = <0>;
		qcom,bam-pipe-idx-cons = <10>;
		qcom,bam-pipe-idx-prod = <11>;
		qcom,master-id = <86>;
	};

	spmi_bus: qcom,spmi@200f000 {
		compatible = "qcom,spmi-pmic-arb";
		reg = <0x200f000 0x1000>,
			<0x2400000 0x400000>,
			<0x2c00000 0x400000>,
			<0x3800000 0x200000>,
			<0x200a000 0x2100>;
		reg-names = "core", "chnls", "obsrvr", "intr", "cnfg";
		interrupts = <0 190 0>;
		qcom,pmic-arb-channel = <0>;
		qcom,pmic-arb-ee = <0>;
		#interrupt-cells = <3>;
		interrupt-controller;
		#address-cells = <1>;
		#size-cells = <0>;
		cell-index = <0>;
	};

	qcom,msm-imem@8600000 {
		compatible = "qcom,msm-imem";
		reg = <0x08600000 0x1000>; /* Address and size of IMEM */
		ranges = <0x0 0x08600000 0x1000>;
		#address-cells = <1>;
		#size-cells = <1>;

		mem_dump_table@10 {
			compatible = "qcom,msm-imem-mem_dump_table";
			reg = <0x10 8>;
		};

		restart_reason@65c {
			compatible = "qcom,msm-imem-restart_reason";
			reg = <0x65c 4>;
		};

		boot_stats@6b0 {
			compatible = "qcom,msm-imem-boot_stats";
			reg = <0x6b0 32>;
		};

		pil@94c {
			compatible = "qcom,msm-imem-pil";
			reg = <0x94c 200>;
		};
	};

	qcom,venus@1de0000 {
		compatible = "qcom,pil-tz-generic";
		reg = <0x1de0000 0x4000>;

		vdd-supply = <&gdsc_venus>;
		qcom,proxy-reg-names = "vdd";
		clocks = <&clock_gcc clk_gcc_venus0_vcodec0_clk>,
			 <&clock_gcc clk_gcc_venus0_ahb_clk>,
			 <&clock_gcc clk_gcc_venus0_axi_clk>,
			 <&clock_gcc clk_gcc_crypto_clk>,
			 <&clock_gcc clk_gcc_crypto_ahb_clk>,
			 <&clock_gcc clk_gcc_crypto_axi_clk>,
			 <&clock_gcc clk_crypto_clk_src>;

		clock-names = "core_clk", "iface_clk",
				"bus_clk", "scm_core_clk",
				"scm_iface_clk", "scm_bus_clk",
				"scm_core_clk_src";
		qcom,proxy-clock-names =  "core_clk", "iface_clk",
					"bus_clk", "scm_core_clk",
					"scm_iface_clk", "scm_bus_clk",
					"scm_core_clk_src";
		qcom,scm_core_clk_src-freq = <80000000>;

		qcom,pas-id = <9>;
		qcom,proxy-timeout-ms = <5000>;
		qcom,firmware-name = "venus";
		linux,contiguous-region = <&venus_qseecom_mem>;
	};

	qcom,msm-thermal {
		compatible = "qcom,msm-thermal";
		qcom,sensor-id = <5>;
		qcom,poll-ms = <250>;
		qcom,limit-temp = <60>;
		qcom,temp-hysteresis = <10>;
		qcom,freq-step = <2>;
		qcom,freq-control-mask = <0xf>;
		qcom,core-limit-temp = <80>;
		qcom,core-temp-hysteresis = <10>;
		qcom,core-control-mask = <0xe>;
		qcom,hotplug-temp = <110>;
		qcom,hotplug-temp-hysteresis = <20>;
		qcom,cpu-sensors = "tsens_tz_sensor5", "tsens_tz_sensor5",
				"tsens_tz_sensor4", "tsens_tz_sensor4";
		qcom,freq-mitigation-temp = <110>;
		qcom,freq-mitigation-temp-hysteresis = <20>;
		qcom,freq-mitigation-value = <960000>;
		qcom,freq-mitigation-control-mask = <0x01>;
		qcom,vdd-restriction-temp = <5>;
		qcom,vdd-restriction-temp-hysteresis = <10>;
		vdd-dig-supply = <&pm8916_s1_floor_corner>;

		qcom,vdd-dig-rstr{
			qcom,vdd-rstr-reg = "vdd-dig";
			qcom,levels = <5 7 7>; /* Nominal, Super Turbo, Super Turbo */
			qcom,min-level = <1>; /* No Request */
		};

		qcom,vdd-apps-rstr{
			qcom,vdd-rstr-reg = "vdd-apps";
			qcom,levels = <533330 800000 998400>;
			qcom,freq-req;
		};
	};

	qcom,bcl {
		compatible = "qcom,bcl";
	};

	qcom,memshare {
		compatible = "qcom,memshare";

		qcom,client_1 {
			compatible = "memshare,peripheral";
			qcom,peripheral-size = <2097152>;
			label = "modem";
		};
	};

	qcom,mss@4080000 {
		compatible = "qcom,pil-q6v56-mss";
		reg = <0x04080000 0x100>,
		      <0x04020000 0x040>,
		      <0x01810000 0x004>,
		      <0x0194f000 0x010>,
		      <0x01950000 0x008>,
		      <0x01951000 0x008>;
		reg-names = "qdsp6_base", "rmb_base", "restart_reg_sec",
				"halt_q6", "halt_modem", "halt_nc";

		interrupts = <0 24 1>;
		vdd_cx-supply = <&pm8916_s1_corner>;
		vdd_mx-supply = <&pm8916_l3>;
		vdd_mx-uV = <1050000>;
		vdd_pll-supply = <&pm8916_l7>;
		qcom,vdd_pll = <1800000>;

		clocks = <&clock_rpm clk_xo_pil_mss_clk>,
			 <&clock_gcc clk_gcc_mss_cfg_ahb_clk>,
			 <&clock_gcc clk_gcc_mss_q6_bimc_axi_clk>,
			 <&clock_gcc clk_gcc_boot_rom_ahb_clk>;
		clock-names = "xo", "iface_clk", "bus_clk", "mem_clk";
		qcom,proxy-clock-names = "xo";
		qcom,active-clock-names = "iface_clk", "bus_clk", "mem_clk";

		qcom,is-loadable;
		qcom,firmware-name = "modem";
		qcom,pil-self-auth;

		/* GPIO inputs from mss */
		qcom,gpio-err-fatal = <&smp2pgpio_ssr_smp2p_1_in 0 0>;
		qcom,gpio-err-ready = <&smp2pgpio_ssr_smp2p_1_in 1 0>;
		qcom,gpio-proxy-unvote = <&smp2pgpio_ssr_smp2p_1_in 2 0>;
		qcom,gpio-stop-ack = <&smp2pgpio_ssr_smp2p_1_in 3 0>;

		/* GPIO output to mss */
		qcom,gpio-force-stop = <&smp2pgpio_ssr_smp2p_1_out 0 0>;
		linux,contiguous-region = <&modem_adsp_mem>;
	};

	qcom,vidc@1d00000 {
		compatible = "qcom,msm-vidc";
		reg = <0x01d00000 0xff000>;
		interrupts = <0 44 0>;
		venus-supply = <&gdsc_venus>;
		clocks = <&clock_gcc clk_gcc_venus0_vcodec0_clk>,
			 <&clock_gcc clk_gcc_venus0_ahb_clk>,
			 <&clock_gcc clk_gcc_venus0_axi_clk>;
		clock-names = "core_clk", "iface_clk", "bus_clk";
		qcom,clock-names = "core_clk", "iface_clk", "bus_clk";
		qcom,clock-configs = <0x1 0x0 0x0>;
		qcom,sw-power-collapse;
		qcom,load-freq-tbl = <352800 228570000 0xffffffff>,
			<244800 160000000 0xffffffff>,
			<108000 100000000 0xffffffff>;
		qcom,hfi = "venus";
		qcom,reg-presets = <0xE0020 0x05555556>,
			<0xE0024 0x05555556>,
			<0x80124 0x00000003>;
		qcom,buffer-type-tz-usage-table = <0x241 0x1>,
			<0x106 0x2>,
			<0x480 0x3>;
		qcom,max-hw-load = <352800>; /* 720p @ 30 + 1080p @ 30 */
		qcom,enable-idle-indicator;
		qcom,vidc-iommu-domains {
			qcom,domain-ns {
				qcom,vidc-domain-phandle = <&venus_domain_ns>;
				qcom,vidc-partition-buffer-types = <0x7ff>,
							<0x800>;
			};
			qcom,domain-sec-bs {
				qcom,vidc-domain-phandle = <&venus_domain_sec_bitstream>;
				qcom,vidc-partition-buffer-types = <0x241>;
			};
			qcom,domain-sec-px {
				qcom,vidc-domain-phandle = <&venus_domain_sec_pixel>;
				qcom,vidc-partition-buffer-types = <0x106>;
			};
			qcom,domain-sec-np {
				qcom,vidc-domain-phandle = <&venus_domain_sec_non_pixel>;
				qcom,vidc-partition-buffer-types = <0x480>;
			};
		};
		qcom,msm-bus-clients {
			qcom,msm-bus-client@0 {
				qcom,msm-bus,name = "venc-ddr";
				qcom,msm-bus,num-cases = <4>;
				qcom,msm-bus,num-paths = <1>;
				qcom,msm-bus,vectors-KBps =
					<63 512 0 0>,
					<63 512 133600 674400>,
					<63 512 400900 1079000>,
					<63 512 908600 1537600>;
				qcom,bus-configs = <0x01000414>;
			};

			qcom,msm-bus-client@1 {
				qcom,msm-bus,name = "vdec-ddr";
				qcom,msm-bus,num-cases = <4>;
				qcom,msm-bus,num-paths = <1>;
				qcom,msm-bus,vectors-KBps =
					<63 512 0 0>,
					<63 512 99600 831900>,
					<63 512 298900 831900>,
					<63 512 677600 1331000>;
				qcom,bus-configs = <0x030fcfff>;
			};
		};
	};

	qcom,pronto@a21b000 {
		compatible = "qcom,pil-tz-generic";
		reg = <0x0a21b000 0x3000>;
		interrupts = <0 149 1>;

		vdd_pronto_pll-supply = <&pm8916_l7>;
		qcom,proxy-reg-names = "vdd_pronto_pll";
		qcom,vdd_pronto_pll-uV-uA = <1800000 18000>;
		clocks = <&clock_rpm clk_xo_pil_pronto_clk>,
			 <&clock_gcc clk_gcc_crypto_clk>,
			 <&clock_gcc clk_gcc_crypto_ahb_clk>,
			 <&clock_gcc clk_gcc_crypto_axi_clk>,
			 <&clock_gcc clk_crypto_clk_src>;

		clock-names = "xo", "scm_core_clk", "scm_iface_clk",
				"scm_bus_clk", "scm_core_clk_src";
		qcom,proxy-clock-names = "xo", "scm_core_clk", "scm_iface_clk",
					"scm_bus_clk", "scm_core_clk_src";
		qcom,scm_core_clk_src-freq = <80000000>;

		qcom,pas-id = <6>;
		qcom,proxy-timeout-ms = <10000>;
		qcom,smem-id = <422>;
		qcom,firmware-name = "wcnss";

		/* GPIO inputs from wcnss */
		qcom,gpio-err-fatal = <&smp2pgpio_ssr_smp2p_4_in 0 0>;
		qcom,gpio-err-ready = <&smp2pgpio_ssr_smp2p_4_in 1 0>;
		qcom,gpio-proxy-unvote = <&smp2pgpio_ssr_smp2p_4_in 2 0>;
		qcom,gpio-stop-ack = <&smp2pgpio_ssr_smp2p_4_in 3 0>;

		/* GPIO output to wcnss */
		qcom,gpio-force-stop = <&smp2pgpio_ssr_smp2p_4_out 0 0>;
		linux,contiguous-region = <&peripheral_mem>;
	};

	cpu-pmu {
		compatible = "arm,armv8-pmuv3";
		qcom,irq-is-percpu;
		interrupts = <1 7 0xf00>;
	};

	bimc_sharedmem {
		compatible = "qcom,sharedmem-uio";
		reg = <0x400000 0x80000>;
		reg-names = "bimc";
	};

	qcom,avtimer {
		compatible = "qcom,avtimer";
		reg = <0x0770600C 0x4>,
			<0x07706010 0x4>;
		reg-names = "avtimer_lsb_addr", "avtimer_msb_addr";
		qcom,clk_div = <27>;
	};
};

&gdsc_venus {
	status = "okay";
};

&gdsc_mdss {
	status = "okay";
};

&gdsc_jpeg {
	status = "okay";
};

&gdsc_vfe {
	status = "okay";
};

&gdsc_oxili_gx {
	clock-names = "core_clk";
	clocks = <&clock_gcc clk_gfx3d_clk_src>;
	qcom,enable-root-clk;
	status = "okay";
};

#include "msm-pm8916-rpm-regulator.dtsi"
#include "msm-pm8916.dtsi"
#include "msm8916-regulator.dtsi"
#include "msm8916-pm.dtsi"

&pm8916_vadc {
	chan@0 {
		label = "usb_in";
		reg = <0>;
		qcom,decimation = <0>;
		qcom,pre-div-channel-scaling = <7>;
		qcom,calibration-type = "absolute";
		qcom,scale-function = <0>;
		qcom,hw-settle-time = <0>;
		qcom,fast-avg-setup = <0>;
	};

	chan@2 {
		label = "ireg_fb";
		reg = <2>;
		qcom,decimation = <0>;
		qcom,pre-div-channel-scaling = <6>;
		qcom,calibration-type = "absolute";
		qcom,scale-function = <0>;
		qcom,hw-settle-time = <0>;
		qcom,fast-avg-setup = <0>;
	};

	chan@5 {
		label = "vcoin";
		reg = <5>;
		qcom,decimation = <0>;
		qcom,pre-div-channel-scaling = <1>;
		qcom,calibration-type = "absolute";
		qcom,scale-function = <0>;
		qcom,hw-settle-time = <0>;
		qcom,fast-avg-setup = <0>;
	};

	chan@6 {
		label = "vbat_sns";
		reg = <6>;
		qcom,decimation = <0>;
		qcom,pre-div-channel-scaling = <1>;
		qcom,calibration-type = "absolute";
		qcom,scale-function = <0>;
		qcom,hw-settle-time = <0>;
		qcom,fast-avg-setup = <0>;
	};

	chan@7 {
		label = "vph_pwr";
		reg = <7>;
		qcom,decimation = <0>;
		qcom,pre-div-channel-scaling = <1>;
		qcom,calibration-type = "absolute";
		qcom,scale-function = <0>;
		qcom,hw-settle-time = <0>;
		qcom,fast-avg-setup = <0>;
	};

	chan@b {
		label = "chg_temp";
		reg = <0xb>;
		qcom,decimation = <0>;
		qcom,pre-div-channel-scaling = <0>;
		qcom,calibration-type = "absolute";
		qcom,scale-function = <3>;
		qcom,hw-settle-time = <0>;
		qcom,fast-avg-setup = <0>;
	};

	chan@30 {
		label = "batt_therm";
		reg = <0x30>;
		qcom,decimation = <0>;
		qcom,pre-div-channel-scaling = <0>;
		qcom,calibration-type = "ratiometric";
		qcom,scale-function = <1>;
		qcom,hw-settle-time = <2>;
		qcom,fast-avg-setup = <0>;
	};

	chan@31 {
		label = "batt_id";
		reg = <0x31>;
		qcom,decimation = <0>;
		qcom,pre-div-channel-scaling = <0>;
		qcom,calibration-type = "ratiometric";
		qcom,scale-function = <0>;
		qcom,hw-settle-time = <2>;
		qcom,fast-avg-setup = <0>;
	};

	chan@36 {
		label = "pa_therm0";
		reg = <0x36>;
		qcom,decimation = <0>;
		qcom,pre-div-channel-scaling = <0>;
		qcom,calibration-type = "ratiometric";
		qcom,scale-function = <2>;
		qcom,hw-settle-time = <2>;
		qcom,fast-avg-setup = <0>;
	};

	chan@32 {
		label = "xo_therm";
		reg = <0x32>;
		qcom,decimation = <0>;
		qcom,pre-div-channel-scaling = <0>;
		qcom,calibration-type = "ratiometric";
		qcom,scale-function = <4>;
		qcom,hw-settle-time = <2>;
		qcom,fast-avg-setup = <0>;
	};

	chan@3c {
		label = "xo_therm_buf";
		reg = <0x3c>;
		qcom,decimation = <0>;
		qcom,pre-div-channel-scaling = <0>;
		qcom,calibration-type = "ratiometric";
		qcom,scale-function = <4>;
		qcom,hw-settle-time = <2>;
		qcom,fast-avg-setup = <0>;
	};
};

&pm8916_adc_tm {
	/* Channel Node */
	chan@30 {
		label = "batt_therm";
		reg = <0x30>;
		qcom,decimation = <0>;
		qcom,pre-div-channel-scaling = <0>;
		qcom,calibration-type = "ratiometric";
		qcom,scale-function = <1>;
		qcom,hw-settle-time = <2>;
		qcom,fast-avg-setup = <3>;
		qcom,btm-channel-number = <0x48>;
	};

	chan@6 {
		label = "vbat_sns";
		reg = <0x6>;
		qcom,decimation = <0>;
		qcom,pre-div-channel-scaling = <1>;
		qcom,calibration-type = "absolute";
		qcom,scale-function = <0>;
		qcom,hw-settle-time = <0>;
		qcom,fast-avg-setup = <3>;
		qcom,btm-channel-number = <0x68>;
	};
};
